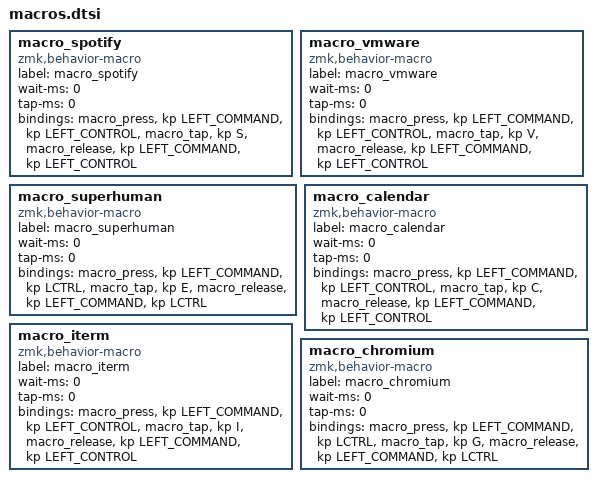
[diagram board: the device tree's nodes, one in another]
macro_spotify: macro_spotify {
    compatible = "zmk,behavior-macro";
    label = "macro_spotify";
    #binding-cells = <0>;
    wait-ms = <0>;
    tap-ms = <0>;
    bindings
        = <&macro_press &kp LEFT_COMMAND &kp LEFT_CONTROL>
        , <&macro_tap &kp S>
        , <&macro_release &kp LEFT_COMMAND &kp LEFT_CONTROL>
        ;
};

macro_vmware: macro_vmware {
    compatible = "zmk,behavior-macro";
    label = "macro_vmware";
    #binding-cells = <0>;
    wait-ms = <0>;
    tap-ms = <0>;
    bindings
        = <&macro_press &kp LEFT_COMMAND &kp LEFT_CONTROL>
        , <&macro_tap &kp V>
        , <&macro_release &kp LEFT_COMMAND &kp LEFT_CONTROL>
        ;
};

macro_superhuman: macro_superhuman {
    compatible = "zmk,behavior-macro";
    label = "macro_superhuman";
    #binding-cells = <0>;
    wait-ms = <0>;
    tap-ms = <0>;
    bindings
        = <&macro_press &kp LEFT_COMMAND &kp LCTRL>
        , <&macro_tap &kp E>
        , <&macro_release &kp LEFT_COMMAND &kp LCTRL>
        ;
};

macro_calendar: macro_calendar {
    compatible = "zmk,behavior-macro";
    label = "macro_calendar";
    #binding-cells = <0>;
    wait-ms = <0>;
    tap-ms = <0>;
    bindings
        = <&macro_press &kp LEFT_COMMAND &kp LEFT_CONTROL>
        , <&macro_tap &kp C>
        , <&macro_release &kp LEFT_COMMAND &kp LEFT_CONTROL>
        ;
};

macro_iterm: macro_iterm {
    compatible = "zmk,behavior-macro";
    label = "macro_iterm";
    #binding-cells = <0>;
    wait-ms = <0>;
    tap-ms = <0>;
    bindings
        = <&macro_press &kp LEFT_COMMAND &kp LEFT_CONTROL>
        , <&macro_tap &kp I>
        , <&macro_release &kp LEFT_COMMAND &kp LEFT_CONTROL>
        ;
};

macro_chromium: macro_chromium {
    compatible = "zmk,behavior-macro";
    label = "macro_chromium";
    #binding-cells = <0>;
    wait-ms = <0>;
    tap-ms = <0>;
    bindings
        = <&macro_press &kp LEFT_COMMAND &kp LCTRL>
        , <&macro_tap &kp G>
        , <&macro_release &kp LEFT_COMMAND &kp LCTRL>
        ;
};
